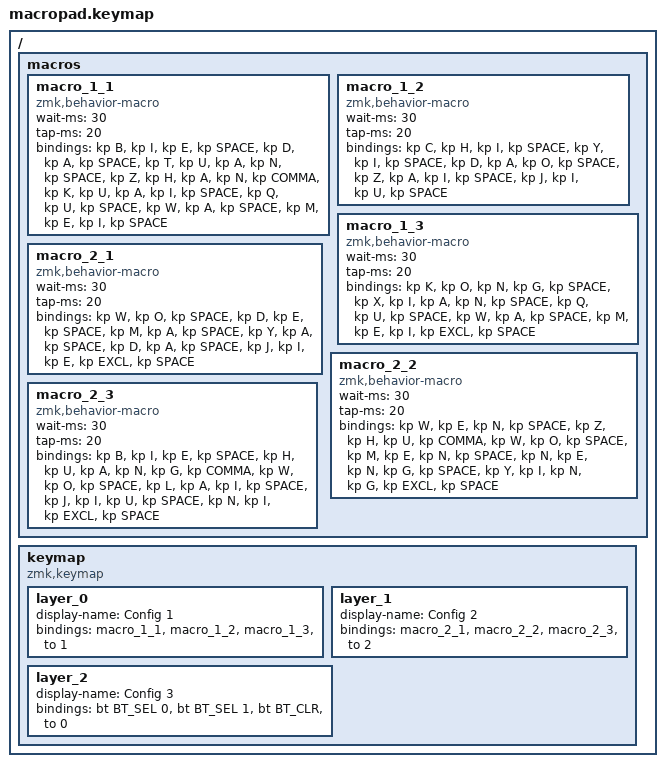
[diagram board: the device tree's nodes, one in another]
#include <behaviors.dtsi>
#include <dt-bindings/zmk/keys.h>
#include <dt-bindings/zmk/bt.h>

/ {
    macros {
        // ================= 配置 1 =================
        macro_1_1: macro_1_1 {
            compatible = "zmk,behavior-macro";
            #binding-cells = <0>;
            wait-ms = <30>;
            tap-ms = <20>;
            bindings = <&kp B &kp I &kp E &kp SPACE &kp D &kp A &kp SPACE &kp T &kp U &kp A &kp N &kp SPACE &kp Z &kp H &kp A &kp N &kp COMMA &kp K &kp U &kp A &kp I &kp SPACE &kp Q &kp U &kp SPACE &kp W &kp A &kp SPACE &kp M &kp E &kp I &kp SPACE>;
        };
        macro_1_2: macro_1_2 {
            compatible = "zmk,behavior-macro";
            #binding-cells = <0>;
            wait-ms = <30>;
            tap-ms = <20>;
            bindings = <&kp C &kp H &kp I &kp SPACE &kp Y &kp I &kp SPACE &kp D &kp A &kp O &kp SPACE &kp Z &kp A &kp I &kp SPACE &kp J &kp I &kp U &kp SPACE>;
        };
        macro_1_3: macro_1_3 {
            compatible = "zmk,behavior-macro";
            #binding-cells = <0>;
            wait-ms = <30>;
            tap-ms = <20>;
            bindings = <&kp K &kp O &kp N &kp G &kp SPACE &kp X &kp I &kp A &kp N &kp SPACE &kp Q &kp U &kp SPACE &kp W &kp A &kp SPACE &kp M &kp E &kp I &kp EXCL &kp SPACE>;
        };

        // ================= 配置 2 =================
        macro_2_1: macro_2_1 {
            compatible = "zmk,behavior-macro";
            #binding-cells = <0>;
            wait-ms = <30>;
            tap-ms = <20>;
            bindings = <&kp W &kp O &kp SPACE &kp D &kp E &kp SPACE &kp M &kp A &kp SPACE &kp Y &kp A &kp SPACE &kp D &kp A &kp SPACE &kp J &kp I &kp E &kp EXCL &kp SPACE>;
        };
        macro_2_2: macro_2_2 {
            compatible = "zmk,behavior-macro";
            #binding-cells = <0>;
            wait-ms = <30>;
            tap-ms = <20>;
            bindings = <&kp W &kp E &kp N &kp SPACE &kp Z &kp H &kp U &kp COMMA &kp W &kp O &kp SPACE &kp M &kp E &kp N &kp SPACE &kp N &kp E &kp N &kp G &kp SPACE &kp Y &kp I &kp N &kp G &kp EXCL &kp SPACE>;
        };
        macro_2_3: macro_2_3 {
            compatible = "zmk,behavior-macro";
            #binding-cells = <0>;
            wait-ms = <30>;
            tap-ms = <20>;
            bindings = <&kp B &kp I &kp E &kp SPACE &kp H &kp U &kp A &kp N &kp G &kp COMMA &kp W &kp O &kp SPACE &kp L &kp A &kp I &kp SPACE &kp J &kp I &kp U &kp SPACE &kp N &kp I &kp EXCL &kp SPACE>;
        };
    };

    keymap {
        compatible = "zmk,keymap";

        // ================= 配置 1 =================
        layer_0 {
            display-name = "Config 1";
            bindings = <
                &macro_1_1     &macro_1_2     &macro_1_3     &to 1
            >;
        };

        // ================= 配置 2 =================
        layer_1 {
            display-name = "Config 2";
            bindings = <
                &macro_2_1     &macro_2_2     &macro_2_3     &to 2
            >;
        };

        // ================= 配置 3 =================
        // 蓝牙控制组（连接 0、连接 1、清除配对、切回组 1）
        layer_2 {
            display-name = "Config 3";
            bindings = <
                &bt BT_SEL 0    &bt BT_SEL 1     &bt BT_CLR       &to 0
            >;
        };
    };
};
